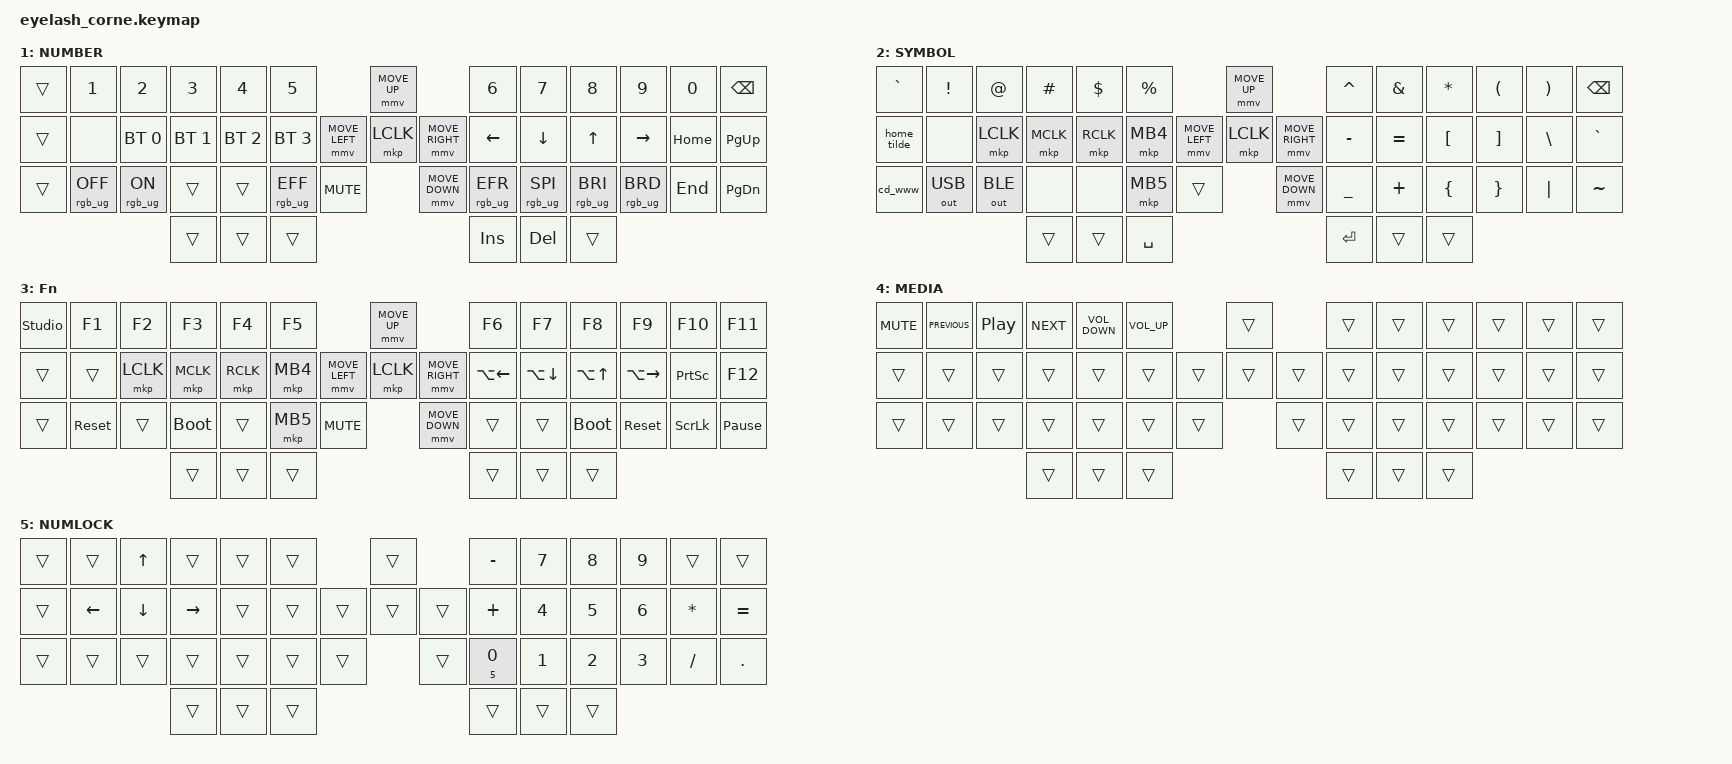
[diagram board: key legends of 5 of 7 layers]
#define ZMK_POINTING_DEFAULT_MOVE_VAL 1200  // 600
#define ZMK_POINTING_DEFAULT_SCRL_VAL 25   // 10

#include <input/processors.dtsi>
#include <zephyr/dt-bindings/input/input-event-codes.h>
#include <behaviors.dtsi>
#include <dt-bindings/zmk/bt.h>
#include <dt-bindings/zmk/keys.h>
#include <dt-bindings/zmk/outputs.h>
#include <dt-bindings/zmk/pointing.h>
#include <dt-bindings/zmk/rgb.h>

&mmv_input_listener { input-processors = <&zip_xy_scaler 2 1>; };

&msc_input_listener { input-processors = <&zip_scroll_scaler 2 1>; };

&msc {
    acceleration-exponent = <1>;      // 0
    time-to-max-speed-ms = <100>;       // 300
    delay-ms = <0>;                   // 0
};

&mmv {
    time-to-max-speed-ms = <500>;
    acceleration-exponent = <1>;
    trigger-period-ms = <16>;
};

/ {
    behaviors {
        td0: td0 {
            compatible = "zmk,behavior-tap-dance";
            display-name = "Shift/Caps Lock Tap Dance";
            #binding-cells = <0>;
            bindings = <&kp LEFT_SHIFT>, <&kp CAPS>;
        };

        f_shift: f_shift {
            compatible = "zmk,behavior-hold-tap";
            #binding-cells = <2>;
            flavor = "tap-preferred";
            tapping-term-ms = <200>;
            bindings = <&kp>, <&kp>;
        };

        j_shift: j_shift {
            compatible = "zmk,behavior-hold-tap";
            #binding-cells = <2>;
            flavor = "tap-preferred";
            tapping-term-ms = <200>;
            bindings = <&kp>, <&kp>;
        };

        bspc_del: backspace_delete {
            compatible = "zmk,behavior-mod-morph";
            #binding-cells = <0>;
            bindings = <&kp BACKSPACE>, <&kp DELETE>;
            mods = <(MOD_LSFT|MOD_RSFT)>;
        };

        g_ctrl: g_ctrl {
            compatible = "zmk,behavior-hold-tap";
            #binding-cells = <2>;
            flavor = "tap-preferred";
            tapping-term-ms = <200>;
            bindings = <&kp>, <&kp>;
        };

        g_graphite_toggle: g_graphite_toggle {
            compatible = "zmk,behavior-hold-tap";
            #binding-cells = <2>;
            flavor = "tap-preferred";
            tapping-term-ms = <1000>;
            bindings = <&tog>, <&g_ctrl>;
        };

        h_ctrl: h_ctrl {
            compatible = "zmk,behavior-hold-tap";
            #binding-cells = <2>;
            flavor = "tap-preferred";
            tapping-term-ms = <200>;
            bindings = <&kp>, <&kp>;
        };

        y_cmd: y_cmd {
            compatible = "zmk,behavior-hold-tap";
            #binding-cells = <2>;
            flavor = "tap-preferred";
            tapping-term-ms = <200>;
            bindings = <&kp>, <&kp>;
        };

        n_word_left: n_word_left {
            compatible = "zmk,behavior-hold-tap";
            #binding-cells = <2>;
            flavor = "tap-preferred";
            tapping-term-ms = <200>;
            bindings = <&kp>, <&kp>;
        };

        m_word_right: m_word_right {
            compatible = "zmk,behavior-hold-tap";
            #binding-cells = <2>;
            flavor = "tap-preferred";
            tapping-term-ms = <200>;
            bindings = <&kp>, <&kp>;
        };

        q_ctrl1: q_ctrl1 {
            compatible = "zmk,behavior-hold-tap";
            #binding-cells = <2>;
            flavor = "tap-preferred";
            tapping-term-ms = <400>;
            bindings = <&kp>, <&kp>;
        };

        w_ctrl2: w_ctrl2 {
            compatible = "zmk,behavior-hold-tap";
            #binding-cells = <2>;
            flavor = "tap-preferred";
            tapping-term-ms = <400>;
            bindings = <&kp>, <&kp>;
        };

        e_ctrl3: e_ctrl3 {
            compatible = "zmk,behavior-hold-tap";
            #binding-cells = <2>;
            flavor = "tap-preferred";
            tapping-term-ms = <400>;
            bindings = <&kp>, <&kp>;
        };

        r_ctrl4: r_ctrl4 {
            compatible = "zmk,behavior-hold-tap";
            #binding-cells = <2>;
            flavor = "tap-preferred";
            tapping-term-ms = <400>;
            bindings = <&kp>, <&kp>;
        };

        e_long_hold: e_long_hold {
            compatible = "zmk,behavior-hold-tap";
            #binding-cells = <2>;
            flavor = "tap-preferred";
            tapping-term-ms = <1500>;
            bindings = <&kp>, <&kp>;
        };

        r_long_hold: r_long_hold {
            compatible = "zmk,behavior-hold-tap";
            #binding-cells = <2>;
            flavor = "tap-preferred";
            tapping-term-ms = <1500>;
            bindings = <&kp>, <&kp>;
        };

        u_long_hold: u_long_hold {
            compatible = "zmk,behavior-hold-tap";
            #binding-cells = <2>;
            flavor = "tap-preferred";
            tapping-term-ms = <1500>;
            bindings = <&kp>, <&kp>;
        };

        cmd_esc_ctrl_c: cmd_esc_ctrl_c {
            compatible = "zmk,behavior-mod-morph";
            #binding-cells = <0>;
            bindings = <&kp ESC>, <&kp LC(C)>;
            mods = <(MOD_LGUI|MOD_RGUI)>;
        };

        p_screenshot: p_screenshot {
            compatible = "zmk,behavior-hold-tap";
            #binding-cells = <2>;
            flavor = "tap-preferred";
            tapping-term-ms = <500>;
            bindings = <&kp>, <&kp>;
        };

        s_screenshot: s_screenshot {
            compatible = "zmk,behavior-hold-tap";
            #binding-cells = <2>;
            flavor = "tap-preferred";
            tapping-term-ms = <500>;
            bindings = <&kp>, <&kp>;
        };

        l_lockscreen: l_lockscreen {
            compatible = "zmk,behavior-hold-tap";
            #binding-cells = <2>;
            flavor = "tap-preferred";
            tapping-term-ms = <1000>;
            bindings = <&kp>, <&kp>;
        };

        home_tilde: home_tilde {
            compatible = "zmk,behavior-macro";
            #binding-cells = <0>;
            bindings = <&kp TILDE &kp FSLH>;
        };

        cd_www: cd_www {
            compatible = "zmk,behavior-macro";
            #binding-cells = <0>;
            bindings = <&kp C &kp D &kp SPACE &kp TILDE &kp FSLH &kp W &kp W &kp W &kp FSLH>;
        };

        media_layer: media_layer {
            compatible = "zmk,behavior-hold-tap";
            #binding-cells = <2>;
            flavor = "tap-preferred";
            tapping-term-ms = <200>;
            bindings = <&mo>, <&kp>;
        };

        a_screenshotToBuffer: a_screenshotToBuffer {
            compatible = "zmk,behavior-hold-tap";
            #binding-cells = <2>;
            flavor = "tap-preferred";
            tapping-term-ms = <500>;
            bindings = <&kp>, <&kp>;
        };

        n_numlock: n_numlock {
            compatible = "zmk,behavior-hold-tap";
            #binding-cells = <2>;
            flavor = "tap-preferred";
            tapping-term-ms = <1000>;
            bindings = <&numlock_tog>, <&kp>;
        };

        numlock_tog: numlock_toggle_with_led {
            compatible = "zmk,behavior-macro";
            #binding-cells = <0>;
            bindings
                = <&macro_tap &tog 5>
                , <&macro_tap &rgb_ug RGB_TOG>
                , <&macro_tap &rgb_ug RGB_COLOR_HSB(30,100,50)>
                ;
        };

    };

    combos {
        compatible = "zmk,combos";
        
        // Russian letter х (kh) - combo of Y + U
        combo_kh {
            timeout-ms = <50>;
            key-positions = <7 8>; // Y and U positions
            bindings = <&kp LBKT>; // [ key produces х in Russian layout
            layers = <0>;
        };
        
        // Russian letter ъ (hard sign) - combo of U + I
        combo_hard_sign {
            timeout-ms = <50>;
            key-positions = <8 9>; // U and I positions
            bindings = <&kp RBKT>; // ] key produces ъ in Russian layout
            layers = <0>;
        };
        
        // Russian letter ё (yo) - combo of I + O
        combo_yo {
            timeout-ms = <50>;
            key-positions = <9 10>; // I and O positions
            bindings = <&kp GRAVE>; // ` key produces ё in Russian layout
            layers = <0>;
        };
        
        
    };

    rgb_encoder: rgb_encoder {
        compatible = "zmk,behavior-sensor-rotate";
        #sensor-binding-cells = <0>;
        bindings = <&rgb_ug RGB_BRI>, <&rgb_ug RGB_BRD>;
    };

    scroll_encoder: scroll_encoder {
        compatible = "zmk,behavior-sensor-rotate";
        #sensor-binding-cells = <0>;
        bindings = <&msc SCRL_DOWN>, <&msc SCRL_UP>;

        tap-ms = <100>;
    };

    keymap {
        compatible = "zmk,keymap";

        default_layer {
            display-name = "QWERTY";
            bindings = <
&cmd_esc_ctrl_c    &q_ctrl1 LC(N1) Q  &w_ctrl2 LC(N2) W  &e_ctrl3 LC(N3) E  &r_ctrl4 LC(N4) R  &kp T                               &kp UP                &y_cmd LGUI Y  &u_long_hold LC(LS(U)) U  &kp I      &kp O    &p_screenshot LG(LS(N4)) P     &bspc_del
&kp TAB    &a_screenshotToBuffer LG(LC(LS(N4))) A  &s_screenshot LG(LS(N4)) S  &kp D     &f_shift LSHIFT F  &g_graphite_toggle 6 LCTRL G           &kp LEFT  &kp ENTER  &kp RIGHT  &h_ctrl RCTRL H  &j_shift RSHIFT J  &kp K      &l_lockscreen LG(LC(Q)) L    &kp SEMI  &kp SQT
&kp LALT  &kp Z  &kp X  &kp C     &kp V  &media_layer 4 B        &media_layer 3 SPACE              &kp DOWN              &n_numlock 5 N  &m_word_right LA(RIGHT) M  &kp COMMA  &kp DOT  &kp FSLH  &kp LS(COLON)
                         &kp LGUI  &mo 1  &lt 3 SPACE                                               &lt 3 ENTER  &mo 2  &kp RALT
            >;

             sensor-bindings = <&inc_dec_kp C_VOLUME_UP C_VOLUME_DOWN>;

           
        };

        lower_layer {
            display-name = "NUMBER";
            bindings = <
&trans  &kp N1           &kp N2          &kp N3        &kp N4        &kp N5                                         &mmv MOVE_UP                     &kp N6           &kp N7           &kp N8           &kp N9           &kp N0    &kp BSPC
&trans  &none            &bt BT_SEL 0    &bt BT_SEL 1  &bt BT_SEL 2  &bt BT_SEL 3                   &mmv MOVE_LEFT  &mkp LCLK       &mmv MOVE_RIGHT  &kp LEFT         &kp DOWN         &kp UP           &kp RIGHT        &kp HOME  &kp PG_UP
&trans  &rgb_ug RGB_OFF  &rgb_ug RGB_ON  &trans        &trans        &rgb_ug RGB_EFF  &kp C_MUTE                    &mmv MOVE_DOWN                   &rgb_ug RGB_EFR  &rgb_ug RGB_SPI  &rgb_ug RGB_BRI  &rgb_ug RGB_BRD  &kp END   &kp PG_DN
                                         &trans        &trans        &trans                                                                          &kp INS          &kp DEL          &trans
            >;

            sensor-bindings = <&scroll_encoder>;
        };

        raise_layer {
            display-name = "SYMBOL";
            bindings = <
&kp GRAVE  &kp EXCL      &kp AT        &kp HASH   &kp DLLR   &kp PRCNT                            &mmv MOVE_UP                     &kp CARET  &kp AMPS   &kp ASTRK  &kp LPAR  &kp RPAR  &kp BSPC
&home_tilde  &none         &mkp LCLK     &mkp MCLK  &mkp RCLK  &mkp MB4             &mmv MOVE_LEFT  &mkp LCLK       &mmv MOVE_RIGHT  &kp MINUS  &kp EQUAL  &kp LBKT   &kp RBKT  &kp BSLH  &kp GRAVE
&cd_www  &out OUT_USB  &out OUT_BLE  &none      &none      &mkp MB5   &trans                    &mmv MOVE_DOWN                   &kp UNDER  &kp PLUS   &kp LBRC   &kp RBRC  &kp PIPE  &kp TILDE
                                    &trans     &trans     &kp SPACE                                                             &kp RET    &trans     &trans
            >;

            sensor-bindings = <&scroll_encoder>;
        };

        layer_3 {
            display-name = "Fn";
            bindings = <
&studio_unlock  &kp F1      &kp F2     &kp F3       &kp F4     &kp F5                                  &mmv MOVE_UP                     &kp F6       &kp F7     &kp F8       &kp F9      &kp F10          &kp F11
&trans          &trans      &mkp LCLK  &mkp MCLK    &mkp RCLK  &mkp MB4                &mmv MOVE_LEFT  &mkp LCLK       &mmv MOVE_RIGHT  &kp LA(LEFT)     &kp LA(DOWN)   &kp LA(UP)       &kp LA(RIGHT)   &kp PRINTSCREEN  &kp F12
&trans          &sys_reset  &trans     &bootloader  &trans     &mkp MB5  &kp C_MUTE                    &mmv MOVE_DOWN                   &trans       &trans     &bootloader  &sys_reset  &kp SCROLLLOCK   &kp PAUSE_BREAK
                                       &trans       &trans     &trans                                                                   &trans       &trans     &trans
            >;

            sensor-bindings = <&scroll_encoder>;
        };

        media_layer {
            display-name = "MEDIA";
            bindings = <
&kp C_MUTE      &kp C_PREVIOUS  &kp C_PLAY_PAUSE  &kp C_NEXT  &kp C_VOLUME_DOWN  &kp C_VOLUME_UP                               &trans                     &trans  &trans  &trans  &trans  &trans  &trans
&trans          &trans          &trans            &trans      &trans             &trans                    &trans  &trans  &trans  &trans             &trans  &trans  &trans  &trans  &trans
&trans          &trans          &trans            &trans      &trans             &trans        &trans                    &trans                     &trans  &trans  &trans  &trans  &trans  &trans
                                                  &trans      &trans             &trans                                                               &trans  &trans  &trans
            >;

            sensor-bindings = <&inc_dec_kp C_VOLUME_UP C_VOLUME_DOWN>;
        };

        numlock_layer {
            display-name = "NUMLOCK";
            bindings = <
&trans  &trans    &kp UP    &trans    &trans    &trans                          &trans  &kp MINUS  &kp N7  &kp N8     &kp N9     &trans        &trans
&trans  &kp LEFT  &kp DOWN  &kp RIGHT &trans    &trans          &trans  &trans  &trans  &kp PLUS   &kp N4  &kp N5     &kp N6     &kp ASTERISK  &kp EQUAL
&trans  &trans    &trans    &trans    &trans    &trans          &trans          &trans  &n_numlock 5 N0     &kp N1  &kp N2     &kp N3     &kp FSLH      &kp DOT
                            &trans    &trans    &trans                          &trans  &trans     &trans
            >;
            
            sensor-bindings = <&inc_dec_kp C_VOLUME_UP C_VOLUME_DOWN>;
        };

        graphite_layer {
            display-name = "GRAPHITE";
            bindings = <
&cmd_esc_ctrl_c    &kp B  &kp L  &kp D  &kp W  &kp Z                               &kp UP                &kp SQT  &kp F  &kp O  &kp U  &kp J     &bspc_del
&kp TAB    &kp N  &kp R  &kp T  &kp S  &g_graphite_toggle 6 LCTRL G           &kp LEFT  &kp ENTER  &kp RIGHT  &kp Y  &kp H  &kp E      &kp I    &kp A  &kp SEMI
&kp LALT  &kp Q  &kp X  &kp M     &kp C  &kp V        &media_layer 3 SPACE              &kp DOWN              &kp K  &kp P  &kp COMMA  &kp DOT  &kp FSLH  &kp LS(COLON)
                         &kp LGUI  &mo 1  &lt 3 SPACE                                               &lt 3 ENTER  &mo 2  &kp RALT
            >;

             sensor-bindings = <&inc_dec_kp C_VOLUME_UP C_VOLUME_DOWN>;
        };
    };
};
